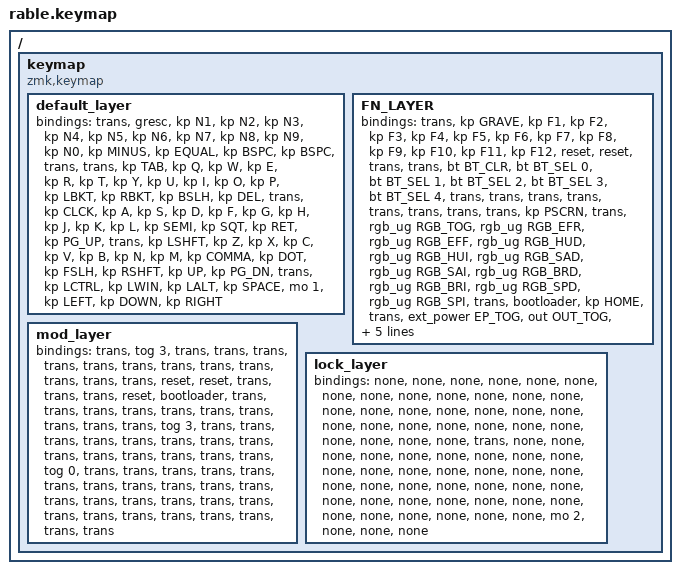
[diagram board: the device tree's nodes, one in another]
/*
 * Copyright (c) 2021 Nick Winans
 *
 * SPDX-License-Identifier: MIT
 */

#include <behaviors.dtsi>
#include <dt-bindings/zmk/keys.h>
#include <dt-bindings/zmk/bt.h>
#include <dt-bindings/zmk/rgb.h>
#include <dt-bindings/zmk/ext_power.h>
#include <dt-bindings/zmk/outputs.h>

/ {
    keymap {
        compatible = "zmk,keymap";

        default_layer {
            bindings = <
 &trans  &gresc  &kp N1  &kp N2  &kp N3  &kp N4  &kp N5  &kp N6  &kp N7  &kp N8  &kp N9  &kp N0  &kp MINUS  &kp EQUAL  &kp BSPC  &kp BSPC  &trans  &trans  &kp TAB   &kp Q   &kp W   &kp E   &kp R   &kp T   &kp Y   &kp U   &kp I   &kp O   &kp P  &kp LBKT  &kp RBKT  &kp BSLH  &kp DEL  &trans  &kp CLCK   &kp A   &kp S   &kp D   &kp F   &kp G   &kp H   &kp J   &kp K   &kp L  &kp SEMI  &kp SQT  &kp RET  &kp PG_UP  &trans  &kp LSHFT   &kp Z   &kp X   &kp C   &kp V   &kp B   &kp N   &kp M  &kp COMMA  &kp DOT  &kp FSLH  &kp RSHFT  &kp UP  &kp PG_DN  &trans  &kp LCTRL  &kp LWIN  &kp LALT  &kp SPACE   &mo 1  &kp LEFT  &kp DOWN  &kp RIGHT
            >;
        };

        FN_LAYER {
            bindings = <
 &trans  &kp GRAVE  &kp F1  &kp F2  &kp F3  &kp F4  &kp F5  &kp F6  &kp F7  &kp F8  &kp F9  &kp F10  &kp F11  &kp F12  &reset  &reset  &trans  &trans  &bt BT_CLR  &bt BT_SEL 0  &bt BT_SEL 1  &bt BT_SEL 2  &bt BT_SEL 3  &bt BT_SEL 4  &trans  &trans  &trans  &trans  &trans  &trans  &trans  &trans  &kp PSCRN  &trans  &rgb_ug RGB_TOG  &rgb_ug RGB_EFR  &rgb_ug RGB_EFF  &rgb_ug RGB_HUD  &rgb_ug RGB_HUI  &rgb_ug RGB_SAD  &rgb_ug RGB_SAI  &rgb_ug RGB_BRD  &rgb_ug RGB_BRI  &rgb_ug RGB_SPD  &rgb_ug RGB_SPI  &trans  &bootloader  &kp HOME  &trans  &ext_power EP_TOG  &out OUT_TOG  &out OUT_USB  &out OUT_BLE  &trans  &trans  &trans  &trans  &trans  &trans  &trans  &trans  &kp C_VOL_UP  &kp END  &trans  &trans  &trans  &trans   &mo 2  &trans  &kp C_PREV  &kp C_VOL_DN  &kp C_NEXT
            >;
        };

        mod_layer {
            bindings = <
 &trans  &tog 3  &trans  &trans  &trans  &trans  &trans  &trans  &trans  &trans  &trans  &trans  &trans  &trans  &reset  &reset  &trans  &trans  &trans  &reset  &bootloader  &trans  &trans  &trans  &trans  &trans  &trans  &trans  &trans  &trans  &trans  &tog 3  &trans  &trans  &trans  &trans  &trans  &trans  &trans  &trans  &trans  &trans  &trans  &trans  &trans  &trans  &tog 0  &trans  &trans  &trans  &trans  &trans  &trans  &trans  &trans  &trans  &trans  &trans  &trans  &trans  &trans  &trans  &trans  &trans  &trans  &trans  &trans  &trans  &trans  &trans  &trans  &trans
            >;
        };

        lock_layer {
            bindings = <
  &none   &none   &none   &none   &none   &none   &none   &none   &none   &none   &none   &none   &none   &none   &none   &none   &none   &none   &none   &none   &none   &none   &none   &none   &none   &none   &none   &none   &none   &none   &none  &trans   &none   &none   &none   &none   &none   &none   &none   &none   &none   &none   &none   &none   &none   &none   &none   &none   &none   &none   &none   &none   &none   &none   &none   &none   &none   &none   &none   &none   &none   &none   &none   &none   &none   &none   &none   &none   &mo 2   &none   &none   &none
            >;
        };
    };
};
